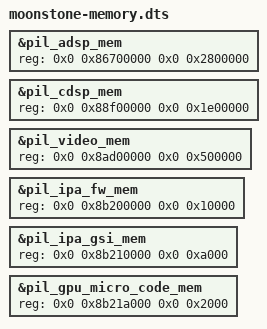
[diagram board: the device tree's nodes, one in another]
&pil_adsp_mem {
	reg = <0x0 0x86700000 0x0 0x2800000>;
};

&pil_cdsp_mem {
	reg = <0x0 0x88f00000 0x0 0x1e00000>;
};

&pil_video_mem {
	reg = <0x0 0x8ad00000 0x0 0x500000>;
};

&pil_ipa_fw_mem {
	reg = <0x0 0x8b200000 0x0 0x10000>;
};

&pil_ipa_gsi_mem {
	reg = <0x0 0x8b210000 0x0 0xa000>;
};

&pil_gpu_micro_code_mem {
	reg = <0x0 0x8b21a000 0x0 0x2000>;
};
